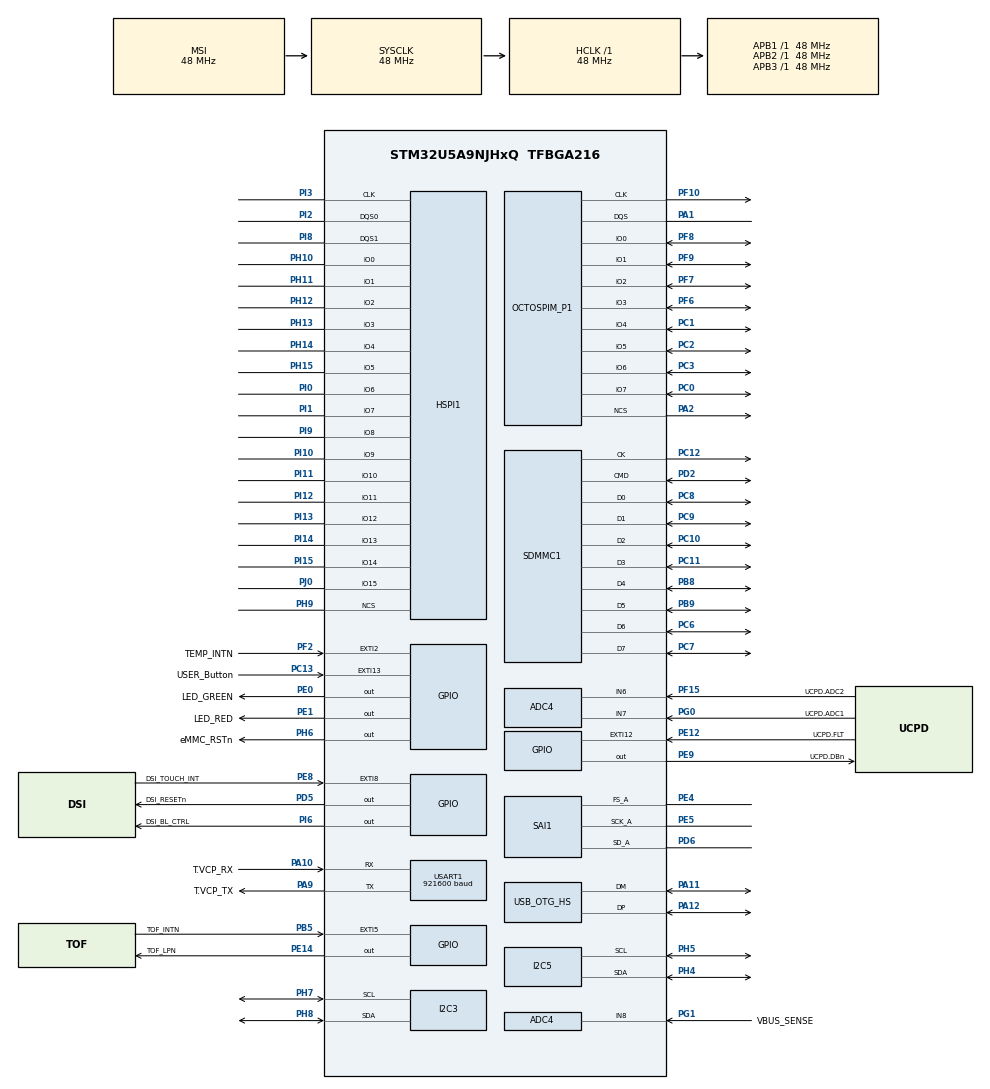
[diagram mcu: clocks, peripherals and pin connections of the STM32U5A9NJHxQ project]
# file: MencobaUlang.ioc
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ADC4.Channel-0\#ChannelRegularConversion=ADC_CHANNEL_6
ADC4.NbrOfConversion=1
ADC4.NbrOfConversionFlag=1
ADC4.OffsetNumber-0\#ChannelRegularConversion=ADC_OFFSET_NONE
ADC4.Rank-0\#ChannelRegularConversion=1
ADC4.RankArg-0\#ChannelRegularConversion=ADC4_REGULAR_RANK_1
ADC4.SamplingTime-0\#ChannelRegularConversion=ADC4_SAMPLINGTIME_COMMON_1
ADC4.SelectedChannel=ADC_CHANNEL_6|ADC_CHANNEL_7|ADC_CHANNEL_8
CORTEX_M33_NS.userName=CORTEX_M33
GPDMA1.CIRCULARMODE_GPDMACH0=ENABLE
GPDMA1.DESTDATAWIDTH_GPDMACH0=DMA_DEST_DATAWIDTH_WORD
GPDMA1.DESTINC_GPDMACH0=DMA_DINC_INCREMENTED
GPDMA1.DIRECTION_GPDMACH1=DMA_MEMORY_TO_PERIPH
GPDMA1.IPHANDLE_GPDMACH0-SIMPLEREQUEST_GPDMACH0=__NULL
GPDMA1.IPHANDLE_GPDMACH1-SIMPLEREQUEST_GPDMACH1=__NULL
GPDMA1.PRIORITY_GPDMACH1=DMA_LOW_PRIORITY_HIGH_WEIGHT
GPDMA1.PRIORITY_LL_CIRCULAR_GPDMACH0=DMA_LOW_PRIORITY_HIGH_WEIGHT
GPDMA1.REQUEST_GPDMACH0=GPDMA1_REQUEST_SAI1_A
GPDMA1.REQUEST_GPDMACH1=GPDMA1_REQUEST_USART1_TX
GPDMA1.SRCDATAWIDTH_GPDMACH0=DMA_SRC_DATAWIDTH_WORD
GPDMA1.SRCINC_GPDMACH1=DMA_SINC_INCREMENTED
I2C3.Timing=0x20303E5D
I2C5.Timing=0x20303E5D
Mcu.Family=STM32U5
Mcu.Name=STM32U5A9NJHxQ
Mcu.Package=TFBGA216
NVIC.GPDMA1_Channel0_IRQn=true\:0\:0\:false\:false\:true\:false\:true\:true
NVIC.GPDMA1_Channel1_IRQn=true\:0\:0\:false\:false\:true\:false\:true\:true
NVIC.PriorityGroup=NVIC_PRIORITYGROUP_4
NVIC.SAI1_IRQn=true\:0\:0\:false\:false\:true\:true\:true\:true
NVIC.USART1_IRQn=true\:0\:0\:false\:false\:true\:true\:true\:true
PA1.Mode=OCTOSPI1_Port1_DQS
PA1.Signal=OCTOSPIM_P1_DQS
PA10.GPIO_Label=T.VCP_RX
PA10.Mode=Asynchronous
PA10.Signal=USART1_RX
PA11.Mode=Internal_Phy_Host
PA11.Signal=USB_OTG_HS_DM
PA12.Mode=Internal_Phy_Host
PA12.Signal=USB_OTG_HS_DP
PA13\ (JTMS/SWDIO).Mode=Serial_Wire
PA13\ (JTMS/SWDIO).Signal=DEBUG_JTMS-SWDIO
PA14\ (JTCK/SWCLK).Mode=Serial_Wire
PA14\ (JTCK/SWCLK).Signal=DEBUG_JTCK-SWCLK
PA2.Mode=OCTOSPI1_Port1_NCS
PA2.Signal=OCTOSPIM_P1_NCS
PA9.GPIO_Label=T.VCP_TX
PA9.Mode=Asynchronous
PA9.Signal=USART1_TX
PB5.GPIO_Label=TOF_INTN
PB5.Signal=GPXTI5
PB8.Mode=mmc_8_bits_Wide_bus
PB8.Signal=SDMMC1_D4
PB9.Mode=mmc_8_bits_Wide_bus
PB9.Signal=SDMMC1_D5
PC0.Mode=OCTOSPI1_IOH_Port1H
PC0.Signal=OCTOSPIM_P1_IO7
PC1.Mode=OCTOSPI1_IOH_Port1H
PC1.Signal=OCTOSPIM_P1_IO4
PC10.Mode=mmc_8_bits_Wide_bus
PC10.Signal=SDMMC1_D2
PC11.Mode=mmc_8_bits_Wide_bus
PC11.Signal=SDMMC1_D3
PC12.Mode=mmc_8_bits_Wide_bus
PC12.Signal=SDMMC1_CK
PC13.GPIO_Label=USER_Button
PC13.Signal=GPXTI13
PC14-OSC32_IN\ (PC14).Mode=LSE-External-Oscillator
PC14-OSC32_IN\ (PC14).Signal=RCC_OSC32_IN
PC15-OSC32_OUT\ (PC15).Mode=LSE-External-Oscillator
PC15-OSC32_OUT\ (PC15).Signal=RCC_OSC32_OUT
PC2.Mode=OCTOSPI1_IOH_Port1H
PC2.Signal=OCTOSPIM_P1_IO5
PC3.Mode=OCTOSPI1_IOH_Port1H
PC3.Signal=OCTOSPIM_P1_IO6
PC6.Mode=mmc_8_bits_Wide_bus
PC6.Signal=SDMMC1_D6
PC7.Mode=mmc_8_bits_Wide_bus
PC7.Signal=SDMMC1_D7
PC8.Mode=mmc_8_bits_Wide_bus
PC8.Signal=SDMMC1_D0
PC9.Mode=mmc_8_bits_Wide_bus
PC9.Signal=SDMMC1_D1
PD2.Mode=mmc_8_bits_Wide_bus
PD2.Signal=SDMMC1_CMD
PD5.GPIO_Label=DSI_RESETn
PD5.Signal=GPIO_Output
PD6.GPIO_PuPd=GPIO_PULLDOWN
PD6.GPIO_Speed=GPIO_SPEED_FREQ_VERY_HIGH
PD6.Mode=SAI_A_Master
PD6.Signal=SAI1_SD_A
PE0.GPIO_Label=LED_GREEN
PE0.Signal=GPIO_Output
PE1.GPIO_Label=LED_RED
PE1.Signal=GPIO_Output
PE12.GPIO_Label=UCPD.FLT
PE12.Signal=GPXTI12
PE14.GPIO_Label=TOF_LPN
PE14.Signal=GPIO_Output
PE4.GPIO_Speed=GPIO_SPEED_FREQ_VERY_HIGH
PE4.Mode=SAI_A_Master
PE4.Signal=SAI1_FS_A
PE5.GPIO_Speed=GPIO_SPEED_FREQ_VERY_HIGH
PE5.Mode=SAI_A_Master
PE5.Signal=SAI1_SCK_A
PE8.GPIO_Label=DSI_TOUCH_INT
PE8.Signal=GPXTI8
PE9.GPIO_Label=UCPD.DBn
PE9.Signal=GPIO_Output
PF10.Mode=O1_P1_CLK
PF10.Signal=OCTOSPIM_P1_CLK
PF15.GPIO_Label=UCPD.ADC2
PF15.Mode=IN6
PF15.Signal=ADC4_IN6
PF2.GPIO_Label=TEMP_INTN
PF2.Signal=GPXTI2
PF6.Mode=OCTOSPI1_IOL_Port1L
PF6.Signal=OCTOSPIM_P1_IO3
PF7.Mode=OCTOSPI1_IOL_Port1L
PF7.Signal=OCTOSPIM_P1_IO2
PF8.Mode=OCTOSPI1_IOL_Port1L
PF8.Signal=OCTOSPIM_P1_IO0
PF9.Mode=OCTOSPI1_IOL_Port1L
PF9.Signal=OCTOSPIM_P1_IO1
PG0.GPIO_Label=UCPD.ADC1
PG0.Mode=IN7
PG0.Signal=ADC4_IN7
PG1.GPIO_Label=VBUS_SENSE
PG1.Mode=IN8
PG1.Signal=ADC4_IN8
PH0-OSC_IN\ (PH0).Mode=HSE-External-Oscillator
PH0-OSC_IN\ (PH0).Signal=RCC_OSC_IN
PH1-OSC_OUT\ (PH1).Mode=HSE-External-Oscillator
PH1-OSC_OUT\ (PH1).Signal=RCC_OSC_OUT
PH10.Mode=hexa_mode
PH10.Signal=HSPI1_IO0
PH11.Mode=hexa_mode
PH11.Signal=HSPI1_IO1
PH12.Mode=hexa_mode
PH12.Signal=HSPI1_IO2
PH13.Mode=hexa_mode
PH13.Signal=HSPI1_IO3
PH14.Mode=hexa_mode
PH14.Signal=HSPI1_IO4
PH15.Mode=hexa_mode
PH15.Signal=HSPI1_IO5
PH4.Mode=I2C
PH4.Signal=I2C5_SDA
PH5.Mode=I2C
PH5.Signal=I2C5_SCL
PH6.GPIO_Label=eMMC_RSTn
PH6.Signal=GPIO_Output
PH7.Mode=I2C
PH7.Signal=I2C3_SCL
PH8.Mode=I2C
PH8.Signal=I2C3_SDA
PH9.Mode=hexa_mode
PH9.Signal=HSPI1_NCS
PI0.Mode=hexa_mode
PI0.Signal=HSPI1_IO6
PI1.Mode=hexa_mode
PI1.Signal=HSPI1_IO7
PI10.Mode=hexa_mode
PI10.Signal=HSPI1_IO9
PI11.Mode=hexa_mode
PI11.Signal=HSPI1_IO10
PI12.Mode=hexa_mode
PI12.Signal=HSPI1_IO11
PI13.Mode=hexa_mode
PI13.Signal=HSPI1_IO12
PI14.Mode=hexa_mode
PI14.Signal=HSPI1_IO13
PI15.Mode=hexa_mode
PI15.Signal=HSPI1_IO14
PI2.Mode=hexa_mode
PI2.Signal=HSPI1_DQS0
PI3.Mode=hexa_mode
PI3.Signal=HSPI1_CLK
PI6.GPIO_Label=DSI_BL_CTRL
PI6.Signal=GPIO_Output
PI8.Mode=hexa_mode
PI8.Signal=HSPI1_DQS1
PI9.Mode=hexa_mode
PI9.Signal=HSPI1_IO8
PJ0.Mode=hexa_mode
PJ0.Signal=HSPI1_IO15
PWR.PowerMode=PWR_SMPS_SUPPLY
ProjectManager.HeapSize=0x200
ProjectManager.StackSize=0x400
ProjectManager.TargetToolchain=STM32CubeIDE
RCC.ADCFreq_Value=16000000
RCC.AHBFreq_Value=48000000
RCC.APB1Freq_Value=48000000
RCC.APB1TimFreq_Value=48000000
RCC.APB2Freq_Value=48000000
RCC.APB2TimFreq_Value=48000000
RCC.APB3Freq_Value=48000000
RCC.CortexFreq_Value=48000000
RCC.DACCLockSelectionVirtual=RCC_DAC1CLKSOURCE_LSI
RCC.EPOD_VALUE=16000000
RCC.HCLKFreq_Value=48000000
RCC.HSE_VALUE=16000000
RCC.HSI48_VALUE=48000000
RCC.HSI_VALUE=16000000
RCC.LSIDIV_VALUE=32000
RCC.MSIClockRange=RCC_MSIRANGE_0
RCC.MSI_VALUE=48000000
RCC.PLL1P=8
RCC.PLL2FRACN=0
RCC.PLL2M=3
RCC.PLL2N=8
RCC.PLL2P=1
RCC.PLLFRACN=0
RCC.PLLN=8
RCC.SYSCLKFreq_VALUE=48000000
RCC.VCOOutputFreq_Value=128000000
SAI1.AudioFrequency-SAI_A_Master=SAI_AUDIO_FREQUENCY_16K
SAI1.AudioMode-SAI_A_Master=SAI_MODEMASTER_RX
SAI1.BasicDataSize-SAI_A_Master=SAI_PROTOCOL_DATASIZE_32BIT
SAI1.ErrorAudioFreq-SAI_A_Master=4.16 %
SAI1.FIFOThreshold-SAI_A_Master=SAI_FIFOTHRESHOLD_HF
SAI1.InitProtocol-SAI_A_Master=Enable
SAI1.Instance-SAI_A_Master=SAI$Index_Block_A
SAI1.MckOutput-SAI_A_Master=SAI_MCK_OUTPUT_DISABLE
SAI1.MonoStereoMode-SAI_A_Master=SAI_MONOMODE
SAI1.OutputDrive-SAI_A_Master=SAI_OUTPUTDRIVE_ENABLE
SAI1.RealAudioFreq-SAI_A_Master=16.666 KHz
SAI1.VirtualMode-SAI_A_Master=VM_MASTER
SAI1.VirtualProtocol-SAI_A_BASIC=VM_BASIC_PROTOCOL
USART1.BaudRate=921600
USART1.VirtualMode-Asynchronous=VM_ASYNC
USB_OTG_HS.VirtualMode=Host_HS
VP_GPDMA1_VS_GPDMACH0.Mode=SIMPLEREQUEST_GPDMACH0
VP_GPDMA1_VS_GPDMACH1.Mode=SIMPLEREQUEST_GPDMACH1
VP_ICACHE_VS_ICACHE.Mode=DirectMappedCache
VP_LPBAMQUEUE_VS_QUEUE.Mode=QUEUEMODE
VP_MEMORYMAP_VS_MEMORYMAP.Mode=CurAppReg
VP_OCTOSPI1_VS_octo.Mode=octo_mode
VP_PWR_VS_DBSignals.Mode=DisableDeadBatterySignals
VP_PWR_VS_LPOM.Mode=PowerOptimisation
VP_PWR_VS_SECSignals.Mode=Security/Privilege
VP_PWR_Vdda.Mode=isolationVdda
VP_SAI1_VP_$IpInstance_SAIA_SAI_BASIC.Mode=SAI_A_BASIC
board=STM32U5A9J-DK

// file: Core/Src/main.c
/* USER CODE BEGIN Header */
/* ============================================================================
 * Voice Activation Project - Audio Acquisition Stage
 * Board   : STM32U5A9J-DK
 * Mic     : INMP441 (I2S digital MEMS microphone)
 * Path    : SAI1 (I2S RX, 32-bit DMA Circular) -> extract 16-bit MSB ->
 *           USART1 (TX, DMA Normal) -> PC
 * ============================================================================
 */
/* USER CODE END Header */
#include "main.h"
#include "adc.h"
#include "gpdma.h"
#include "hspi.h"
#include "i2c.h"
#include "icache.h"
#include "octospi.h"
#include "sai.h"
#include "sdmmc.h"
#include "usart.h"
#include "usb_otg.h"
#include "gpio.h"

/* USER CODE BEGIN Includes */
#include <string.h>
/* USER CODE END Includes */

/* USER CODE BEGIN PD */
#define HALF_BUFFER_SAMPLES   1600U                      /* jumlah RAW WORD dari DMA per half (BUKAN otomatis = jumlah sample audio asli, lihat catatan di ExtractAndSendHalfBuffer) */
#define FULL_BUFFER_SAMPLES   (HALF_BUFFER_SAMPLES * 2U)  /* total ping-pong buffer */

/* HIPOTESIS yang sedang diuji: SAI1 dikonfigurasi "2 slot" (Stereo frame),
 * artinya tiap frame WS mengirim 2 word DMA (slot Left & Right) meski mic
 * cuma mono -- salah satu slot floating/garbage. ACTIVE_SLOT_OFFSET
 * menentukan slot mana (index genap=0 atau ganjil=1) yang diambil sebagai
 * audio asli. MULAI dari 0 -- kalau hasil rekaman masih noisy/malah lebih
 * aneh, coba ganti ke 1. */
#define ACTIVE_SLOT_OFFSET    0U
/* USER CODE END PD */

/* USER CODE BEGIN PV */
/* Buffer RAW dari SAI1 RX DMA, 32-bit per sample (sesuai SAI Data Size 32 Bits).
 * Tiap word berisi: 24-bit data audio INMP441 (MSB-first) + 8-bit padding nol di LSB.
 * Index 0 .. HALF_BUFFER_SAMPLES-1   -> "half pertama"
 * Index HALF_BUFFER_SAMPLES .. end   -> "half kedua"
 */
static uint32_t audioBufferRaw[FULL_BUFFER_SAMPLES];

/* Buffer hasil ekstraksi 16-bit MSB dari audioBufferRaw, yang akan dikirim
 * ke UART. Dipakai ulang (reuse) untuk half pertama maupun half kedua.
 * Ukuran tetap HALF_BUFFER_SAMPLES (lebih besar dari perlu setelah fix
 * slot -- cukup aman, cuma dipakai sebagian: HALF_BUFFER_SAMPLES/2). */
static uint16_t audioBuffer16[HALF_BUFFER_SAMPLES];

/* Flag untuk menandai buffer mana yang siap diproses & dikirim.
 * Diset di callback ISR, dibaca/diproses di main loop. */
static volatile uint8_t firstHalfReady  = 0;
static volatile uint8_t secondHalfReady = 0;

/* Flag status pengiriman UART, supaya kita tidak menumpuk
 * panggilan HAL_UART_Transmit_DMA sebelum transfer sebelumnya selesai. */
static volatile uint8_t uartTxBusy = 0;

/* Counter untuk deteksi overrun (buffer berikutnya siap sebelum
 * buffer sebelumnya selesai dikirim -> data akan ke-skip) */
static volatile uint32_t overrunCount = 0;
/* USER CODE END PV */

void SystemClock_Config(void);
static void SystemPower_Config(void);
/* USER CODE BEGIN PFP */
static void ExtractAndSendHalfBuffer(uint32_t *rawData, uint16_t sizeInSamples);
/* USER CODE END PFP */

int main(void)
{

  /* MCU Configuration--------------------------------------------------------*/

  /* Reset of all peripherals, Initializes the Flash interface and the Systick. */
  HAL_Init();

  /* Configure the System Power */
  SystemPower_Config();

  /* Configure the system clock */
  SystemClock_Config();

  /* Initialize all configured peripherals */
  MX_GPIO_Init();
  MX_GPDMA1_Init();
  MX_ADC4_Init();
  MX_HSPI1_Init();
  MX_I2C3_Init();
  MX_I2C5_Init();
  MX_ICACHE_Init();
  MX_OCTOSPI1_Init();
  MX_SAI1_Init();
  MX_SDMMC1_MMC_Init();
  MX_USART1_UART_Init();
  MX_USB_OTG_HS_HCD_Init();
  /* USER CODE BEGIN 2 */
  /* Mulai akuisisi audio dari INMP441 via SAI1, mode DMA circular, 32-bit.
   * Karena Circular Mode sudah diaktifkan di CubeMX, panggilan ini
   * HANYA SEKALI di awal -- DMA akan otomatis looping terus menerus.
   * Catatan: parameter ketiga HAL_SAI_Receive_DMA tetap dalam satuan SAMPLE
   * (bukan byte), HAL akan otomatis kalikan dengan lebar data (32-bit/4 byte)
   * sesuai konfigurasi SAI Data Size. */
  if (HAL_SAI_Receive_DMA(&hsai_BlockA1, (uint8_t *)audioBufferRaw, FULL_BUFFER_SAMPLES) != HAL_OK)
  {
      Error_Handler();
  }
  /* USER CODE END 2 */

  /* Infinite loop */
  /* USER CODE BEGIN WHILE */
  while (1)
  {
      /* Cek flag dari callback ISR, proses di main loop (bukan di ISR)
       * supaya ISR tetap ringan dan cepat. */
      if (firstHalfReady)
      {
          firstHalfReady = 0;
          ExtractAndSendHalfBuffer(&audioBufferRaw[0], HALF_BUFFER_SAMPLES);
      }

      if (secondHalfReady)
      {
          secondHalfReady = 0;
          ExtractAndSendHalfBuffer(&audioBufferRaw[HALF_BUFFER_SAMPLES], HALF_BUFFER_SAMPLES);
      }

    /* USER CODE END WHILE */

  }
}

void SystemClock_Config(void)
{
  RCC_OscInitTypeDef RCC_OscInitStruct = {0};
  RCC_ClkInitTypeDef RCC_ClkInitStruct = {0};

  /** Configure the main internal regulator output voltage
  */
  if (HAL_PWREx_ControlVoltageScaling(PWR_REGULATOR_VOLTAGE_SCALE2) != HAL_OK)
  {
    Error_Handler();
  }

  /** Initializes the CPU, AHB and APB buses clocks
  */
  RCC_OscInitStruct.OscillatorType = RCC_OSCILLATORTYPE_HSI|RCC_OSCILLATORTYPE_HSE
                              |RCC_OSCILLATORTYPE_MSI;
  RCC_OscInitStruct.HSEState = RCC_HSE_ON;
  RCC_OscInitStruct.HSIState = RCC_HSI_ON;
  RCC_OscInitStruct.HSICalibrationValue = RCC_HSICALIBRATION_DEFAULT;
  RCC_OscInitStruct.MSIState = RCC_MSI_ON;
  RCC_OscInitStruct.MSICalibrationValue = RCC_MSICALIBRATION_DEFAULT;
  RCC_OscInitStruct.MSIClockRange = RCC_MSIRANGE_0;
  RCC_OscInitStruct.PLL.PLLState = RCC_PLL_ON;
  RCC_OscInitStruct.PLL.PLLSource = RCC_PLLSOURCE_HSE;
  RCC_OscInitStruct.PLL.PLLMBOOST = RCC_PLLMBOOST_DIV1;
  RCC_OscInitStruct.PLL.PLLM = 1;
  RCC_OscInitStruct.PLL.PLLN = 8;
  RCC_OscInitStruct.PLL.PLLP = 8;
  RCC_OscInitStruct.PLL.PLLQ = 2;
  RCC_OscInitStruct.PLL.PLLR = 2;
  RCC_OscInitStruct.PLL.PLLRGE = RCC_PLLVCIRANGE_1;
  RCC_OscInitStruct.PLL.PLLFRACN = 0;
  if (HAL_RCC_OscConfig(&RCC_OscInitStruct) != HAL_OK)
  {
    Error_Handler();
  }

  /** Initializes the CPU, AHB and APB buses clocks
  */
  RCC_ClkInitStruct.ClockType = RCC_CLOCKTYPE_HCLK|RCC_CLOCKTYPE_SYSCLK
                              |RCC_CLOCKTYPE_PCLK1|RCC_CLOCKTYPE_PCLK2
                              |RCC_CLOCKTYPE_PCLK3;
  RCC_ClkInitStruct.SYSCLKSource = RCC_SYSCLKSOURCE_MSI;
  RCC_ClkInitStruct.AHBCLKDivider = RCC_SYSCLK_DIV1;
  RCC_ClkInitStruct.APB1CLKDivider = RCC_HCLK_DIV1;
  RCC_ClkInitStruct.APB2CLKDivider = RCC_HCLK_DIV1;
  RCC_ClkInitStruct.APB3CLKDivider = RCC_HCLK_DIV1;

  if (HAL_RCC_ClockConfig(&RCC_ClkInitStruct, FLASH_LATENCY_1) != HAL_OK)
  {
    Error_Handler();
  }
}

/**
  * @brief Power Configuration
  * @retval None
  */
static void SystemPower_Config(void)
{

  /*
   * Disable the internal Pull-Up in Dead Battery pins of UCPD peripheral
   */
  HAL_PWREx_DisableUCPDDeadBattery();

  /*
   * Switch to SMPS regulator instead of LDO
   */
  if (HAL_PWREx_ConfigSupply(PWR_SMPS_SUPPLY) != HAL_OK)
  {
    Error_Handler();
  }
}

/* USER CODE BEGIN 4 */

/* ============================================================================
 * Fungsi bantu: ekstrak sample audio ASLI dari half-buffer raw SAI,
 * lalu kirim hasil ekstraksi (16-bit) ke USART1 via DMA.
 *
 * FIX SLOT INTERLEAVING (sedang diuji): SAI1 dikonfigurasi "2 slot"
 * (Stereo frame) meski mic mono -- tiap frame WS mengirim 2 raw word DMA
 * (slot Left & Right berselang-seling), tapi cuma SATU slot yang berisi
 * data mic yang valid (slot lainnya floating/garbage, karena L/R pin mic
 * di-GND -> cuma salah satu slot yang "terisi" beneran). Kode SEBELUMNYA
 * mengambil SETIAP raw word tanpa membedakan slot -- ini diduga jadi
 * penyebab noise (separuh "sample" yang dikirim itu garbage, diselang-seling
 * dengan audio asli).
 *
 * Fix: ambil HANYA 1 dari tiap 2 raw word (index genap/ganjil sesuai
 * ACTIVE_SLOT_OFFSET), buang slot yang tidak aktif. Konsekuensi: jumlah
 * sample audio ASLI yang dikirim per half-buffer jadi SETENGAH dari
 * sizeInSamples (raw word count), yaitu HALF_BUFFER_SAMPLES/2 = 800 sample.
 *
 * Kenapa >> 16 (tetap sama seperti sebelumnya): data INMP441 24-bit
 * MSB-first ditempatkan di bit [31:8] dari tiap word 32-bit (bit [7:0]
 * padding nol). Ambil 16 bit teratas = representasi 16-bit paling
 * signifikan dari data audio asli.
 *
 * Jika UART masih sibuk mengirim buffer sebelumnya, data ini akan
 * di-skip dan overrunCount bertambah.
 * ============================================================================
 */
static void ExtractAndSendHalfBuffer(uint32_t *rawData, uint16_t sizeInSamples)
{
    if (uartTxBusy)
    {
        overrunCount++;
        return;
    }

    /* SEMENTARA DI-REVERT ke versi ambil SEMUA raw word (tanpa slot-skip),
     * untuk uji ulang sekarang setelah VDD mic diperbaiki (pakai 3V3
     * eksternal dari ESP32, bukan pin 3V3 STM32 yang bermasalah).
     *
     * Alasan revert: noise yang terlihat sebelumnya kemungkinan besar
     * BUKAN dari slot interleaving (hipotesis "2 slot, Mono"), melainkan
     * dari VDD yang tidak stabil. Fix slot-skip sebelumnya (ambil 1 dari
     * tiap 2 raw word) kemungkinan JUSTRU membuang separuh sample asli
     * yang valid -- ini konsisten dengan gejala "rekaman terdengar sangat
     * dipercepat" (durasi WAV dianggap penuh tapi datanya cuma setengah).
     *
     * Kalau hasil tes ini BERSIH tanpa skip -- teori ini terkonfirmasi,
     * dan versi INI (bukan versi slot-skip) yang dipakai seterusnya.
     * Kalau MASIH noisy -- berarti slot-skip memang perlu, tapi root
     * cause noise sebelumnya harus dipisah dulu dari masalah VDD supaya
     * tidak mencampur dua variabel sekaligus. */
    for (uint16_t i = 0; i < sizeInSamples; i++)
    {
        audioBuffer16[i] = (uint16_t)(rawData[i] >> 16);
    }

    uartTxBusy = 1;
    if (HAL_UART_Transmit_DMA(&huart1, (uint8_t *)audioBuffer16, sizeInSamples * 2U) != HAL_OK)
    {
        uartTxBusy = 0;
        Error_Handler();
    }
}

/* ============================================================================
 * Callback: dipanggil otomatis oleh HAL saat separuh PERTAMA buffer
 * SAI RX selesai diisi DMA (event "Half Transfer").
 * ============================================================================
 */
void HAL_SAI_RxHalfCpltCallback(SAI_HandleTypeDef *hsai)
{
    if (hsai->Instance == hsai_BlockA1.Instance)
    {
        firstHalfReady = 1;
    }
}

/* ============================================================================
 * Callback: dipanggil otomatis oleh HAL saat buffer SAI RX selesai
 * penuh terisi (event "Transfer Complete"). Karena Circular Mode,
 * DMA otomatis lanjut menulis ulang dari awal buffer (half pertama)
 * setelah ini.
 * ============================================================================
 */
void HAL_SAI_RxCpltCallback(SAI_HandleTypeDef *hsai)
{
    if (hsai->Instance == hsai_BlockA1.Instance)
    {
        secondHalfReady = 1;
    }
}

/* ============================================================================
 * Callback: dipanggil otomatis oleh HAL saat transfer USART1 TX (DMA)
 * selesai sepenuhnya. Reset flag busy supaya half-buffer berikutnya
 * boleh diekstrak & dikirim.
 * ============================================================================
 */
void HAL_UART_TxCpltCallback(UART_HandleTypeDef *huart)
{
    if (huart->Instance == huart1.Instance)
    {
        uartTxBusy = 0;
    }
}

/* ============================================================================
 * Callback error handler untuk SAI. Berguna untuk debugging jika ada
 * overrun di sisi SAI/DMA RX sendiri (berbeda dari overrunCount di atas
 * yang menghitung sisi UART TX).
 * ============================================================================
 */
void HAL_SAI_ErrorCallback(SAI_HandleTypeDef *hsai)
{
    if (hsai->Instance == hsai_BlockA1.Instance)
    {
        /* Letakkan breakpoint di sini saat debugging untuk
         * mengetahui apakah SAI mengalami overrun/error lain. */
        __NOP();
    }
}

/* USER CODE END 4 */

void Error_Handler(void)
{
  __disable_irq();
  while (1)
  {
  }
}
